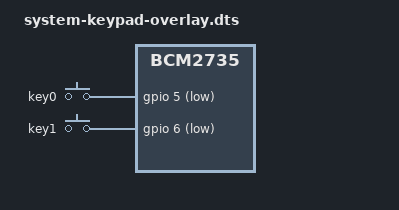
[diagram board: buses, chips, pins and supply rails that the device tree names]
/dts-v1/;
/plugin/;

#include <dt-bindings/gpio/gpio.h>
#include <dt-bindings/input/input.h>

/ {

  compatible = "brcm,bcm2735";

	fragment@0 {
		target = <&gpio>;
		__overlay__ {
			system_keypad_pins: system_keypad_pins {
			  brcm,pins = <5 6>;
			  brcm,function = <0 0>; // 0 = input, 1 = output
			  brcm,pull = <0 0>; // 0 = none, 1 = pull down, 2 = pull up
		  };
	  };
  };

	fragment@1 {
		target-path = "/";
		__overlay__ {
			system_leds: system_keypad {
				compatible = "gpio-keys";
				pinctrl-names = "default";
				pinctrl-0 = <&system_keypad_pins>;
				status = "okay";

				key0: key0 {
					label = "key0";
					gpios = <&gpio 5 GPIO_ACTIVE_LOW>;
					linux,code = <KEY_F10>;
				};

				key1: key1 {
					label = "key1";
					gpios = <&gpio 6 GPIO_ACTIVE_LOW>;
					linux,code = <KEY_F11>;
				};
			};
		};
	};
};
